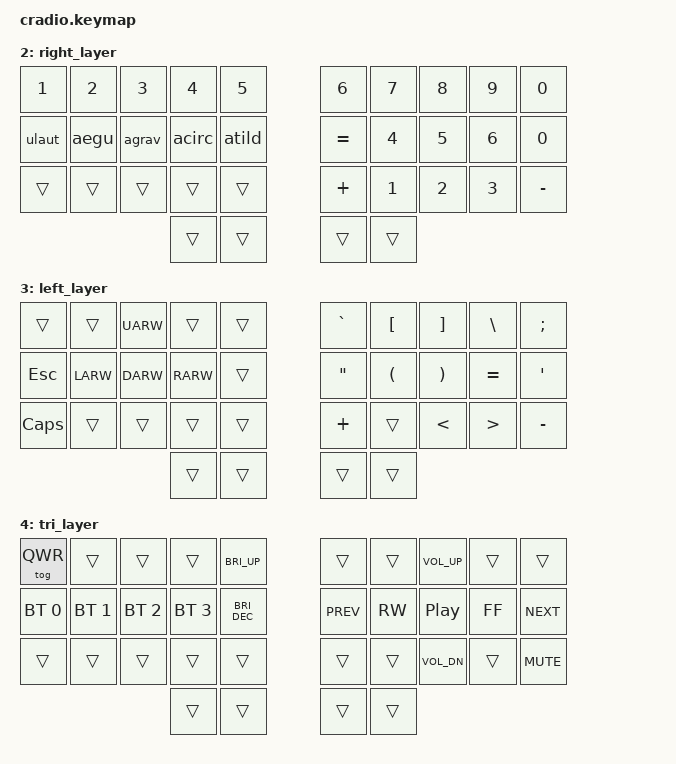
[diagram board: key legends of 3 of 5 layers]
// Copyright (c) 2022 The ZMK Contributors
// SPDX-License-Identifier: MIT

#include <behaviors.dtsi>
#include <dt-bindings/zmk/keys.h>
#include <dt-bindings/zmk/bt.h>
#include <dt-bindings/zmk/outputs.h>

// Home row mods macro
#define HRML(k1,k2,k3,k4) &ht LSHIFT k1  &ht LCTRL k2  &ht LALT k3  &ht LGUI k4
#define HRMR(k1,k2,k3,k4) &ht RGUI k1  &ht RALT k2  &ht RCTRL k3  &ht RSHIFT k4

#define CMK 0
#define QWR 1
#define RIG 2
#define LEF 3
#define TRI 4

/ {
    macros {
        ulaut: ulaut {
            compatible = "zmk,behavior-macro";
            #binding-cells = <0>;
            bindings
                = <&macro_press &kp LALT>
                , <&macro_tap &kp U>
                , <&macro_release &kp LALT>
                ;
        };
        agrav: agrav {
            compatible = "zmk,behavior-macro";
            #binding-cells = <0>;
            bindings
                = <&macro_press &kp LALT>
                , <&macro_tap &kp GRAVE>
                , <&macro_release &kp LALT>
                ;
        };
        aegu: aegu {
            compatible = "zmk,behavior-macro";
            #binding-cells = <0>;
            bindings
                = <&macro_press &kp LALT>
                , <&macro_tap &kp E>
                , <&macro_release &kp LALT>
                ;
        };
        acirc: acirc {
            compatible = "zmk,behavior-macro";
            #binding-cells = <0>;
            bindings
                = <&macro_press &kp LALT>
                , <&macro_tap &kp I>
                , <&macro_release &kp LALT>
                ;
        };
        atild: atild {
            compatible = "zmk,behavior-macro";
            #binding-cells = <0>;
            bindings
                = <&macro_press &kp LALT>
                , <&macro_tap &kp N>
                , <&macro_release &kp LALT>
                ;
        };
    };

    behaviors {
        ht: hold_tap {
            compatible = "zmk,behavior-hold-tap";
            #binding-cells = <2>;
            flavor = "tap-preferred";
            tapping-term-ms = <280>;
            quick-tap-ms = <175>;
            require-prior-idle-ms = <175>;
            bindings = <&kp>, <&kp>;
        };
        smt: space_mod_tap {
            compatible = "zmk,behavior-hold-tap";
            #binding-cells = <2>;
            flavor = "tap-preferred";
            tapping-term-ms = <400>;
            quick-tap-ms = <175>;
            require-prior-idle-ms = <175>;
            bindings = <&kp>, <&kp>;
        };
    };

    conditional_layers {
        compatible = "zmk,conditional-layers";
        tri_layer {
            if-layers = <RIG LEF>;
            then-layer = <TRI>;
        };
    };

    keymap {
        compatible = "zmk,keymap";
        default_layer {
            bindings = <
        //╭──────────┬──────────┬──────────┬──────────┬──────────╮        ╭──────────┬──────────┬──────────┬──────────┬──────────╮
        //│  Q       │  W       │  F       │  P       │  G       │        │  J       │  L       │  U       │  Y       │  ;       │
            &kp Q      &kp W      &kp F      &kp P      &kp G               &kp J      &kp L      &kp U      &kp Y      &kp SEMI
        //├──────────┼──────────┼──────────┼──────────┼──────────┤        ├──────────┼──────────┼──────────┼──────────┼──────────┤
        //│  A       │  R       │  S       │  T       │  D       │        │  H       │  N       │  E       │  I       │  O       │
        	HRML(A,		R,         S,         T)     	&kp D               &kp H      HRMR(N,     E,	      I,		 O)
        //├──────────┼──────────┼──────────┼──────────┼──────────┤        ├──────────┼──────────┼──────────┼──────────┼──────────┤
        //│  Z       │  X       │  C       │  V       │  B       │        │  K       │  M       │ , <      │ . >      │  /       │
            &kp Z      &kp X      &kp C      &kp V      &kp B               &kp K      &kp M      &kp COMMA  &kp DOT    &kp FSLH
        //╰──────────┴──────────┴──────────┼──────────┼──────────┤        ├──────────┼──────────┼──────────┴──────────┴──────────╯
                                         &lt LEF TAB  &mt LSHIFT BSPC      &smt LSHIFT SPACE  &lt RIG ENTER
        //                                 ╰──────────┴──────────╯        ╰──────────┴──────────╯
            >;
        };

        qwerty_layer {
            bindings = <
        //╭──────────┬──────────┬──────────┬──────────┬──────────╮        ╭──────────┬──────────┬──────────┬──────────┬──────────╮
        //│  Q       │  W       │  E       │  R       │  T       │        │  Y       │  U       │  I       │  O       │  P       │
            &kp Q      &kp W      &kp E      &kp R      &kp T               &kp Y      &kp U      &kp I      &kp O      &kp P
        //├──────────┼──────────┼──────────┼──────────┼──────────┤        ├──────────┼──────────┼──────────┼──────────┼──────────┤
        //│  A       │  S       │  D       │  F       │  G       │        │  H       │  J       │  K       │  L       │  ;       │
            HRML(A, 	S,         D,         F)     	&kp G               &kp H      HRMR(J,        K,         L, 	 SEMI)
        //├──────────┼──────────┼──────────┼──────────┼──────────┤        ├──────────┼──────────┼──────────┼──────────┼──────────┤
        //│  Z       │  X       │  C       │  V       │  B       │        │  N       │  M       │ , <      │ . >      │  /       │
            &kp Z      &kp X      &kp C      &kp V      &kp B               &kp N      &kp M      &kp COMMA  &kp DOT    &kp FSLH
        //╰──────────┴──────────┴──────────┼──────────┼──────────┤        ├──────────┼──────────┼──────────┴──────────┴──────────╯
                                           &lt LEF TAB  &mt LSHIFT BSPC    &smt LSHIFT SPACE  &lt RIG ENTER
        //                                 ╰──────────┴──────────╯        ╰──────────┴──────────╯
            >;
        };

        right_layer {
            bindings = <
        //╭──────────┬──────────┬──────────┬──────────┬──────────╮        ╭──────────┬──────────┬──────────┬──────────┬──────────╮
        //│ 1        │ 2        │ 3        │ 4        │ 5        │        │ 6        │ 7        │ 8        │ 9        │ 0        │
            &kp N1     &kp N2     &kp N3     &kp N4     &kp N5              &kp N6     &kp N7     &kp N8     &kp N9     &kp N0
        //├──────────┼──────────┼──────────┼──────────┼──────────┤        ├──────────┼──────────┼──────────┼──────────┼──────────┤
        //│ Umlaut   │ Egu      │ Grav     │ Circ     │  ˜       |        |  =       │ 4        │ 5        │ 6        │  0       │
            &ulaut     &aegu      &agrav     &acirc     &atild              &kp EQUAL  &kp N4     &kp N5     &kp N6     &kp N0
        //├──────────┼──────────┼──────────┼──────────┼──────────┤        ├──────────┼──────────┼──────────┼──────────┼──────────┤
        //│          │          │          │          │          │        │  +       │ 1        │ 2        │ 3        │  -       │
            &trans     &trans     &trans     &trans     &trans              &kp PLUS   &kp N1     &kp N2     &kp N3     &kp MINUS
        //╰──────────┴──────────┴──────────┼──────────┼──────────┤        ├──────────┼──────────┼──────────┴──────────┴──────────╯
                                             &trans     &trans              &trans     &trans
        //                                 ╰──────────┴──────────╯        ╰──────────┴──────────╯
            >;
        };

        left_layer {
            bindings = <
        //╭──────────┬──────────┬──────────┬──────────┬──────────╮        ╭──────────┬──────────┬──────────┬──────────┬──────────╮
        //│          │          │ UP       │          │          │        │  `       │ [        │ ]        │  \       │  :       │
            &trans     &trans     &kp UARW   &trans     &trans              &kp GRAVE  &kp LBKT   &kp RBKT   &kp BSLH   &kp SEMI
        //├──────────┼──────────┼──────────┼──────────┼──────────┤        ├──────────┼──────────┼──────────┼──────────┼──────────┤
        //│ ESC      │ LEFT     │ DOWN     │ RIGHT    │          │        │  "       │   (      │  )       │  =       │  '       │
            &kp ESC    &kp LARW   &kp DARW   &kp RARW   &trans              &kp DQT    &kp LPAR   &kp RPAR   &kp EQUAL  &kp SQT
        //├──────────┼──────────┼──────────┼──────────┼──────────┤        ├──────────┼──────────┼──────────┼──────────┼──────────┤
        //│ CAPS     │          │          │          │          │        │  +       │          │  <       │  >       │  -       │
            &kp CAPS   &trans     &trans     &trans     &trans              &kp PLUS   &trans     &kp LT     &kp GT     &kp MINUS
        //╰──────────┴──────────┴──────────┼──────────┼──────────┤        ├──────────┼──────────┼──────────┴──────────┴──────────╯
                                             &trans     &trans              &trans     &trans
        //                                 ╰──────────┴──────────╯        ╰──────────┴──────────╯
            >;
        };

        tri_layer {
            bindings = <
        //╭───────────┬───────────┬───────────┬───────────┬────────────╮        ╭────────────┬────────────┬──────────┬───────────┬──────────╮
        //│  QWERTY   │           │           │           │ INC BRIGHT │        │            │            │ VOL UP   │           │          │
            &tog QWR    &trans      &trans      &trans      &kp C_BRI_UP         &trans        &trans       &kp C_VOL_UP &trans    &trans
        //├───────────┼───────────┼───────────┼───────────┼────────────┤        ├────────────┼────────────┼──────────┼───────────┼──────────┤
        //│ PROFILE 0 │ PROFILE 1 │ PROFILE 2 │ PROFILE 3 │ DEC BRIGHT │        │ Previous   │ Rewind     │ Pause    │ FF        │ Next     │
            &bt BT_SEL 0 &bt BT_SEL 1 &bt BT_SEL 2 &bt BT_SEL 3 &kp C_BRI_DEC    &kp C_PREV  &kp C_RW    &kp C_PP   &kp C_FF    &kp C_NEXT
        //├───────────┼───────────┼───────────┼───────────┼────────────┤        ├────────────┼────────────┼──────────┼───────────┼──────────┤
        //│           │           │           │           │            │        │            │            │ VOL DOWN │           │ MUTE     │
            &trans       &trans     &trans      &trans      &trans               &trans        &trans       &kp C_VOL_DN &trans    &kp C_MUTE
        //╰───────────┴───────────┴───────────┼───────────┼────────────┤        ├────────────┼────────────┼──────────┴───────────┴──────────╯
                                                &trans      &trans                &trans       &trans
        //                                    ╰───────────┴────────────╯        ╰────────────┴────────────╯
            >;
        };
    };
};

&mt {
    tapping-term-ms = <280>;
};

&lt {
    tapping-term-ms = <170>;
};
